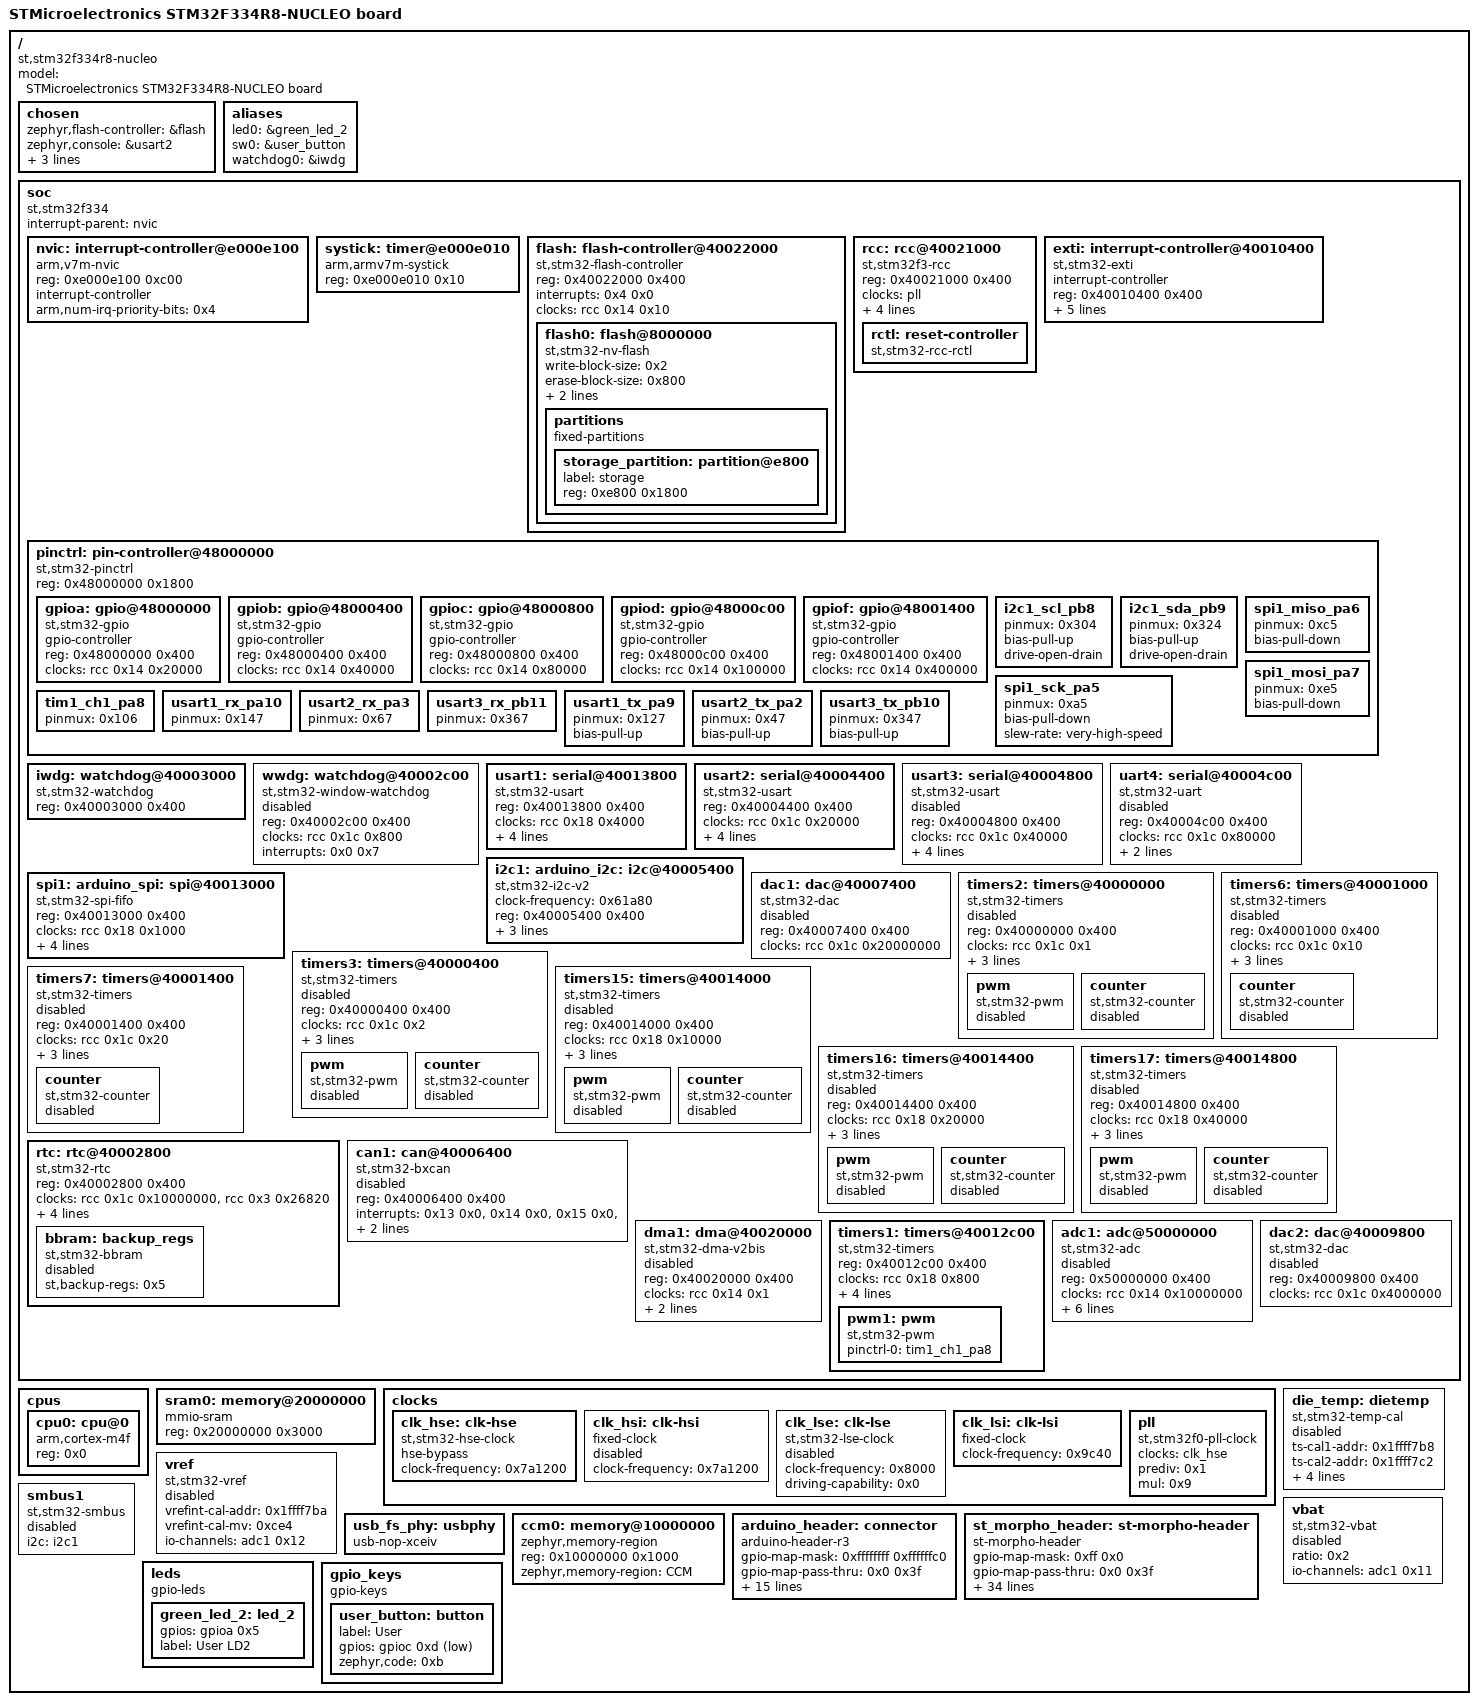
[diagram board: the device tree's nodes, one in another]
/dts-v1/;

/ {
	#address-cells = < 0x1 >;
	#size-cells = < 0x1 >;
	model = "STMicroelectronics STM32F334R8-NUCLEO board";
	compatible = "st,stm32f334r8-nucleo";
	chosen {
		zephyr,flash-controller = &flash;
		zephyr,console = &usart2;
		zephyr,shell-uart = &usart2;
		zephyr,sram = &sram0;
		zephyr,flash = &flash0;
	};
	aliases {
		led0 = &green_led_2;
		sw0 = &user_button;
		watchdog0 = &iwdg;
	};
	soc {
		#address-cells = < 0x1 >;
		#size-cells = < 0x1 >;
		compatible = "st,stm32f334", "st,stm32f3", "simple-bus";
		interrupt-parent = < &nvic >;
		ranges;
		nvic: interrupt-controller@e000e100 {
			#address-cells = < 0x1 >;
			compatible = "arm,v7m-nvic";
			reg = < 0xe000e100 0xc00 >;
			interrupt-controller;
			#interrupt-cells = < 0x2 >;
			arm,num-irq-priority-bits = < 0x4 >;
			phandle = < 0x1 >;
		};
		systick: timer@e000e010 {
			compatible = "arm,armv7m-systick";
			reg = < 0xe000e010 0x10 >;
		};
		flash: flash-controller@40022000 {
			compatible = "st,stm32-flash-controller", "st,stm32f1-flash-controller";
			reg = < 0x40022000 0x400 >;
			interrupts = < 0x4 0x0 >;
			clocks = < &rcc 0x14 0x10 >;
			#address-cells = < 0x1 >;
			#size-cells = < 0x1 >;
			flash0: flash@8000000 {
				compatible = "st,stm32-nv-flash", "soc-nv-flash";
				write-block-size = < 0x2 >;
				erase-block-size = < 0x800 >;
				max-erase-time = < 0x28 >;
				reg = < 0x8000000 0x10000 >;
				partitions {
					compatible = "fixed-partitions";
					#address-cells = < 0x1 >;
					#size-cells = < 0x1 >;
					storage_partition: partition@e800 {
						label = "storage";
						reg = < 0xe800 0x1800 >;
					};
				};
			};
		};
		rcc: rcc@40021000 {
			compatible = "st,stm32f3-rcc";
			#clock-cells = < 0x2 >;
			reg = < 0x40021000 0x400 >;
			clocks = < &pll >;
			clock-frequency = < 0x44aa200 >;
			ahb-prescaler = < 0x1 >;
			apb1-prescaler = < 0x2 >;
			apb2-prescaler = < 0x1 >;
			phandle = < 0x2 >;
			rctl: reset-controller {
				compatible = "st,stm32-rcc-rctl";
				#reset-cells = < 0x1 >;
				phandle = < 0x4 >;
			};
		};
		exti: interrupt-controller@40010400 {
			compatible = "st,stm32-exti";
			interrupt-controller;
			#interrupt-cells = < 0x1 >;
			#address-cells = < 0x1 >;
			reg = < 0x40010400 0x400 >;
			num-lines = < 0x10 >;
			interrupts = < 0x6 0x0 >, < 0x7 0x0 >, < 0x8 0x0 >, < 0x9 0x0 >, < 0xa 0x0 >, < 0x17 0x0 >, < 0x28 0x0 >;
			interrupt-names = "line0", "line1", "line2", "line3", "line4", "line5-9", "line10-15";
			line-ranges = < 0x0 0x1 >, < 0x1 0x1 >, < 0x2 0x1 >, < 0x3 0x1 >, < 0x4 0x1 >, < 0x5 0x5 >, < 0xa 0x6 >;
		};
		pinctrl: pin-controller@48000000 {
			compatible = "st,stm32-pinctrl";
			#address-cells = < 0x1 >;
			#size-cells = < 0x1 >;
			reg = < 0x48000000 0x1800 >;
			gpioa: gpio@48000000 {
				compatible = "st,stm32-gpio";
				gpio-controller;
				#gpio-cells = < 0x2 >;
				reg = < 0x48000000 0x400 >;
				clocks = < &rcc 0x14 0x20000 >;
				phandle = < 0x15 >;
			};
			gpiob: gpio@48000400 {
				compatible = "st,stm32-gpio";
				gpio-controller;
				#gpio-cells = < 0x2 >;
				reg = < 0x48000400 0x400 >;
				clocks = < &rcc 0x14 0x40000 >;
				phandle = < 0x10 >;
			};
			gpioc: gpio@48000800 {
				compatible = "st,stm32-gpio";
				gpio-controller;
				#gpio-cells = < 0x2 >;
				reg = < 0x48000800 0x400 >;
				clocks = < &rcc 0x14 0x80000 >;
				phandle = < 0x16 >;
			};
			gpiod: gpio@48000c00 {
				compatible = "st,stm32-gpio";
				gpio-controller;
				#gpio-cells = < 0x2 >;
				reg = < 0x48000c00 0x400 >;
				clocks = < &rcc 0x14 0x100000 >;
				phandle = < 0x17 >;
			};
			gpiof: gpio@48001400 {
				compatible = "st,stm32-gpio";
				gpio-controller;
				#gpio-cells = < 0x2 >;
				reg = < 0x48001400 0x400 >;
				clocks = < &rcc 0x14 0x400000 >;
				phandle = < 0x18 >;
			};
			i2c1_scl_pb8: i2c1_scl_pb8 {
				pinmux = < 0x304 >;
				bias-pull-up;
				drive-open-drain;
				phandle = < 0xb >;
			};
			i2c1_sda_pb9: i2c1_sda_pb9 {
				pinmux = < 0x324 >;
				bias-pull-up;
				drive-open-drain;
				phandle = < 0xc >;
			};
			spi1_miso_pa6: spi1_miso_pa6 {
				pinmux = < 0xc5 >;
				bias-pull-down;
				phandle = < 0xe >;
			};
			spi1_mosi_pa7: spi1_mosi_pa7 {
				pinmux = < 0xe5 >;
				bias-pull-down;
				phandle = < 0xf >;
			};
			spi1_sck_pa5: spi1_sck_pa5 {
				pinmux = < 0xa5 >;
				bias-pull-down;
				slew-rate = "very-high-speed";
				phandle = < 0xd >;
			};
			tim1_ch1_pa8: tim1_ch1_pa8 {
				pinmux = < 0x106 >;
				phandle = < 0x11 >;
			};
			usart1_rx_pa10: usart1_rx_pa10 {
				pinmux = < 0x147 >;
				phandle = < 0x6 >;
			};
			usart2_rx_pa3: usart2_rx_pa3 {
				pinmux = < 0x67 >;
				phandle = < 0x8 >;
			};
			usart3_rx_pb11: usart3_rx_pb11 {
				pinmux = < 0x367 >;
				phandle = < 0xa >;
			};
			usart1_tx_pa9: usart1_tx_pa9 {
				pinmux = < 0x127 >;
				bias-pull-up;
				phandle = < 0x5 >;
			};
			usart2_tx_pa2: usart2_tx_pa2 {
				pinmux = < 0x47 >;
				bias-pull-up;
				phandle = < 0x7 >;
			};
			usart3_tx_pb10: usart3_tx_pb10 {
				pinmux = < 0x347 >;
				bias-pull-up;
				phandle = < 0x9 >;
			};
		};
		iwdg: watchdog@40003000 {
			compatible = "st,stm32-watchdog";
			reg = < 0x40003000 0x400 >;
			status = "okay";
		};
		wwdg: watchdog@40002c00 {
			compatible = "st,stm32-window-watchdog";
			reg = < 0x40002c00 0x400 >;
			clocks = < &rcc 0x1c 0x800 >;
			interrupts = < 0x0 0x7 >;
			status = "disabled";
		};
		usart1: serial@40013800 {
			compatible = "st,stm32-usart", "st,stm32-uart";
			reg = < 0x40013800 0x400 >;
			clocks = < &rcc 0x18 0x4000 >;
			resets = < &rctl 0x18e >;
			interrupts = < 0x25 0x0 >;
			status = "okay";
			pinctrl-0 = < &usart1_tx_pa9 &usart1_rx_pa10 >;
			pinctrl-names = "default";
			current-speed = < 0x1c200 >;
		};
		usart2: serial@40004400 {
			compatible = "st,stm32-usart", "st,stm32-uart";
			reg = < 0x40004400 0x400 >;
			clocks = < &rcc 0x1c 0x20000 >;
			resets = < &rctl 0x211 >;
			interrupts = < 0x26 0x0 >;
			status = "okay";
			pinctrl-0 = < &usart2_tx_pa2 &usart2_rx_pa3 >;
			pinctrl-names = "default";
			current-speed = < 0x1c200 >;
		};
		usart3: serial@40004800 {
			compatible = "st,stm32-usart", "st,stm32-uart";
			reg = < 0x40004800 0x400 >;
			clocks = < &rcc 0x1c 0x40000 >;
			resets = < &rctl 0x212 >;
			interrupts = < 0x27 0x0 >;
			status = "disabled";
			pinctrl-0 = < &usart3_tx_pb10 &usart3_rx_pb11 >;
			pinctrl-names = "default";
			current-speed = < 0x1c200 >;
		};
		uart4: serial@40004c00 {
			compatible = "st,stm32-uart";
			reg = < 0x40004c00 0x400 >;
			clocks = < &rcc 0x1c 0x80000 >;
			resets = < &rctl 0x213 >;
			interrupts = < 0x34 0x0 >;
			status = "disabled";
		};
		i2c1: arduino_i2c: i2c@40005400 {
			compatible = "st,stm32-i2c-v2";
			clock-frequency = < 0x61a80 >;
			#address-cells = < 0x1 >;
			#size-cells = < 0x0 >;
			reg = < 0x40005400 0x400 >;
			clocks = < &rcc 0x1c 0x200000 >, < &rcc 0x1 0x12430 >;
			interrupts = < 0x1f 0x0 >, < 0x20 0x0 >;
			interrupt-names = "event", "error";
			status = "okay";
			pinctrl-0 = < &i2c1_scl_pb8 &i2c1_sda_pb9 >;
			pinctrl-names = "default";
			phandle = < 0x14 >;
		};
		spi1: arduino_spi: spi@40013000 {
			compatible = "st,stm32-spi-fifo", "st,stm32-spi";
			#address-cells = < 0x1 >;
			#size-cells = < 0x0 >;
			reg = < 0x40013000 0x400 >;
			clocks = < &rcc 0x18 0x1000 >;
			interrupts = < 0x23 0x5 >;
			status = "okay";
			pinctrl-0 = < &spi1_sck_pa5 &spi1_miso_pa6 &spi1_mosi_pa7 >;
			pinctrl-names = "default";
			cs-gpios = < &gpiob 0x6 0x11 >;
		};
		dac1: dac@40007400 {
			compatible = "st,stm32-dac";
			reg = < 0x40007400 0x400 >;
			clocks = < &rcc 0x1c 0x20000000 >;
			status = "disabled";
			#io-channel-cells = < 0x1 >;
		};
		timers2: timers@40000000 {
			compatible = "st,stm32-timers";
			reg = < 0x40000000 0x400 >;
			clocks = < &rcc 0x1c 0x1 >;
			resets = < &rctl 0x200 >;
			interrupts = < 0x1c 0x0 >;
			interrupt-names = "global";
			st,prescaler = < 0x0 >;
			status = "disabled";
			pwm {
				compatible = "st,stm32-pwm";
				status = "disabled";
				#pwm-cells = < 0x3 >;
			};
			counter {
				compatible = "st,stm32-counter";
				status = "disabled";
			};
		};
		timers3: timers@40000400 {
			compatible = "st,stm32-timers";
			reg = < 0x40000400 0x400 >;
			clocks = < &rcc 0x1c 0x2 >;
			resets = < &rctl 0x201 >;
			interrupts = < 0x1d 0x0 >;
			interrupt-names = "global";
			st,prescaler = < 0x0 >;
			status = "disabled";
			pwm {
				compatible = "st,stm32-pwm";
				status = "disabled";
				#pwm-cells = < 0x3 >;
			};
			counter {
				compatible = "st,stm32-counter";
				status = "disabled";
			};
		};
		timers6: timers@40001000 {
			compatible = "st,stm32-timers";
			reg = < 0x40001000 0x400 >;
			clocks = < &rcc 0x1c 0x10 >;
			resets = < &rctl 0x204 >;
			interrupts = < 0x36 0x0 >;
			interrupt-names = "global";
			st,prescaler = < 0x0 >;
			status = "disabled";
			counter {
				compatible = "st,stm32-counter";
				status = "disabled";
			};
		};
		timers7: timers@40001400 {
			compatible = "st,stm32-timers";
			reg = < 0x40001400 0x400 >;
			clocks = < &rcc 0x1c 0x20 >;
			resets = < &rctl 0x205 >;
			interrupts = < 0x37 0x0 >;
			interrupt-names = "global";
			st,prescaler = < 0x0 >;
			status = "disabled";
			counter {
				compatible = "st,stm32-counter";
				status = "disabled";
			};
		};
		timers15: timers@40014000 {
			compatible = "st,stm32-timers";
			reg = < 0x40014000 0x400 >;
			clocks = < &rcc 0x18 0x10000 >;
			resets = < &rctl 0x190 >;
			interrupts = < 0x18 0x0 >;
			interrupt-names = "global";
			st,prescaler = < 0x0 >;
			status = "disabled";
			pwm {
				compatible = "st,stm32-pwm";
				status = "disabled";
				#pwm-cells = < 0x3 >;
			};
			counter {
				compatible = "st,stm32-counter";
				status = "disabled";
			};
		};
		timers16: timers@40014400 {
			compatible = "st,stm32-timers";
			reg = < 0x40014400 0x400 >;
			clocks = < &rcc 0x18 0x20000 >;
			resets = < &rctl 0x191 >;
			interrupts = < 0x19 0x0 >;
			interrupt-names = "global";
			st,prescaler = < 0x0 >;
			status = "disabled";
			pwm {
				compatible = "st,stm32-pwm";
				status = "disabled";
				#pwm-cells = < 0x3 >;
			};
			counter {
				compatible = "st,stm32-counter";
				status = "disabled";
			};
		};
		timers17: timers@40014800 {
			compatible = "st,stm32-timers";
			reg = < 0x40014800 0x400 >;
			clocks = < &rcc 0x18 0x40000 >;
			resets = < &rctl 0x192 >;
			interrupts = < 0x1a 0x0 >;
			interrupt-names = "global";
			st,prescaler = < 0x0 >;
			status = "disabled";
			pwm {
				compatible = "st,stm32-pwm";
				status = "disabled";
				#pwm-cells = < 0x3 >;
			};
			counter {
				compatible = "st,stm32-counter";
				status = "disabled";
			};
		};
		rtc: rtc@40002800 {
			compatible = "st,stm32-rtc";
			reg = < 0x40002800 0x400 >;
			clocks = < &rcc 0x1c 0x10000000 >, < &rcc 0x3 0x26820 >;
			interrupts = < 0x29 0x0 >;
			prescaler = < 0x8000 >;
			alarms-count = < 0x2 >;
			alrm-exti-line = < 0x11 >;
			status = "okay";
			bbram: backup_regs {
				compatible = "st,stm32-bbram";
				st,backup-regs = < 0x5 >;
				status = "disabled";
			};
		};
		can1: can@40006400 {
			compatible = "st,stm32-bxcan";
			reg = < 0x40006400 0x400 >;
			interrupts = < 0x13 0x0 >, < 0x14 0x0 >, < 0x15 0x0 >, < 0x16 0x0 >;
			interrupt-names = "TX", "RX0", "RX1", "SCE";
			clocks = < &rcc 0x1c 0x2000000 >;
			status = "disabled";
		};
		dma1: dma@40020000 {
			compatible = "st,stm32-dma-v2bis";
			#dma-cells = < 0x2 >;
			reg = < 0x40020000 0x400 >;
			clocks = < &rcc 0x14 0x1 >;
			interrupts = < 0xb 0x0 0xc 0x0 0xd 0x0 0xe 0x0 0xf 0x0 0x10 0x0 0x11 0x0 >;
			status = "disabled";
		};
		timers1: timers@40012c00 {
			compatible = "st,stm32-timers";
			reg = < 0x40012c00 0x400 >;
			clocks = < &rcc 0x18 0x800 >;
			resets = < &rctl 0x18b >;
			interrupts = < 0x18 0x0 >, < 0x19 0x0 >, < 0x1a 0x0 >, < 0x1b 0x0 >;
			interrupt-names = "brk", "up", "trgcom", "cc";
			st,prescaler = < 0x2710 >;
			status = "okay";
			pwm1: pwm {
				compatible = "st,stm32-pwm";
				status = "okay";
				#pwm-cells = < 0x3 >;
				pinctrl-0 = < &tim1_ch1_pa8 >;
				pinctrl-names = "default";
			};
		};
		adc1: adc@50000000 {
			compatible = "st,stm32-adc";
			reg = < 0x50000000 0x400 >;
			clocks = < &rcc 0x14 0x10000000 >;
			interrupts = < 0x12 0x0 >;
			status = "disabled";
			#io-channel-cells = < 0x1 >;
			resolutions = < 0x60630c 0x51630c 0x42630c 0x33630c >;
			sampling-times = < 0x2 0x3 0x5 0x8 0x14 0x3e 0xb6 0x25a >;
			st,adc-sequencer = < 0x1 >;
			phandle = < 0x13 >;
		};
		dac2: dac@40009800 {
			compatible = "st,stm32-dac";
			reg = < 0x40009800 0x400 >;
			clocks = < &rcc 0x1c 0x4000000 >;
			status = "disabled";
			#io-channel-cells = < 0x1 >;
		};
	};
	cpus {
		#address-cells = < 0x1 >;
		#size-cells = < 0x0 >;
		cpu0: cpu@0 {
			device_type = "cpu";
			compatible = "arm,cortex-m4f";
			reg = < 0x0 >;
		};
	};
	sram0: memory@20000000 {
		compatible = "mmio-sram";
		reg = < 0x20000000 0x3000 >;
	};
	clocks {
		clk_hse: clk-hse {
			#clock-cells = < 0x0 >;
			compatible = "st,stm32-hse-clock";
			status = "okay";
			hse-bypass;
			clock-frequency = < 0x7a1200 >;
			phandle = < 0x12 >;
		};
		clk_hsi: clk-hsi {
			#clock-cells = < 0x0 >;
			compatible = "fixed-clock";
			clock-frequency = < 0x7a1200 >;
			status = "disabled";
		};
		clk_lse: clk-lse {
			#clock-cells = < 0x0 >;
			compatible = "st,stm32-lse-clock";
			clock-frequency = < 0x8000 >;
			driving-capability = < 0x0 >;
			status = "disabled";
		};
		clk_lsi: clk-lsi {
			#clock-cells = < 0x0 >;
			compatible = "fixed-clock";
			clock-frequency = < 0x9c40 >;
			status = "okay";
		};
		pll: pll {
			#clock-cells = < 0x0 >;
			compatible = "st,stm32f0-pll-clock";
			status = "okay";
			clocks = < &clk_hse >;
			prediv = < 0x1 >;
			mul = < 0x9 >;
			phandle = < 0x3 >;
		};
	};
	die_temp: dietemp {
		compatible = "st,stm32-temp-cal";
		ts-cal1-addr = < 0x1ffff7b8 >;
		ts-cal2-addr = < 0x1ffff7c2 >;
		ts-cal1-temp = < 0x1e >;
		ts-cal2-temp = < 0x6e >;
		ts-cal-vrefanalog = < 0xce4 >;
		io-channels = < &adc1 0x10 >;
		status = "disabled";
	};
	vref: vref {
		compatible = "st,stm32-vref";
		vrefint-cal-addr = < 0x1ffff7ba >;
		vrefint-cal-mv = < 0xce4 >;
		io-channels = < &adc1 0x12 >;
		status = "disabled";
	};
	vbat: vbat {
		compatible = "st,stm32-vbat";
		ratio = < 0x2 >;
		io-channels = < &adc1 0x11 >;
		status = "disabled";
	};
	usb_fs_phy: usbphy {
		compatible = "usb-nop-xceiv";
		#phy-cells = < 0x0 >;
	};
	smbus1: smbus1 {
		compatible = "st,stm32-smbus";
		#address-cells = < 0x1 >;
		#size-cells = < 0x0 >;
		i2c = < &i2c1 >;
		status = "disabled";
	};
	ccm0: memory@10000000 {
		compatible = "zephyr,memory-region", "st,stm32-ccm";
		reg = < 0x10000000 0x1000 >;
		zephyr,memory-region = "CCM";
	};
	arduino_header: connector {
		compatible = "arduino-header-r3";
		#gpio-cells = < 0x2 >;
		gpio-map-mask = < 0xffffffff 0xffffffc0 >;
		gpio-map-pass-thru = < 0x0 0x3f >;
		gpio-map = < 0x0 0x0 &gpioa 0x0 0x0 >, < 0x1 0x0 &gpioa 0x1 0x0 >, < 0x2 0x0 &gpioa 0x4 0x0 >, < 0x3 0x0 &gpiob 0x0 0x0 >, < 0x4 0x0 &gpioc 0x1 0x0 >, < 0x5 0x0 &gpioc 0x0 0x0 >, < 0x6 0x0 &gpioa 0x3 0x0 >, < 0x7 0x0 &gpioa 0x2 0x0 >, < 0x8 0x0 &gpioa 0xa 0x0 >, < 0x9 0x0 &gpiob 0x3 0x0 >, < 0xa 0x0 &gpiob 0x5 0x0 >, < 0xb 0x0 &gpiob 0x4 0x0 >, < 0xc 0x0 &gpiob 0xa 0x0 >, < 0xd 0x0 &gpioa 0x8 0x0 >, < 0xe 0x0 &gpioa 0x9 0x0 >, < 0xf 0x0 &gpioc 0x7 0x0 >, < 0x10 0x0 &gpiob 0x6 0x0 >, < 0x11 0x0 &gpioa 0x7 0x0 >, < 0x12 0x0 &gpioa 0x6 0x0 >, < 0x13 0x0 &gpioa 0x5 0x0 >, < 0x14 0x0 &gpiob 0x9 0x0 >, < 0x15 0x0 &gpiob 0x8 0x0 >;
	};
	st_morpho_header: st-morpho-header {
		compatible = "st-morpho-header";
		#gpio-cells = < 0x2 >;
		gpio-map-mask = < 0xff 0x0 >;
		gpio-map-pass-thru = < 0x0 0x3f >;
		gpio-map = < 0x0 0x0 &gpioc 0xa 0x0 >, < 0x1 0x0 &gpioc 0xb 0x0 >, < 0x2 0x0 &gpioc 0xc 0x0 >, < 0x3 0x0 &gpiod 0x2 0x0 >, < 0xc 0x0 &gpioa 0xd 0x0 >, < 0xe 0x0 &gpioa 0xe 0x0 >, < 0x10 0x0 &gpioa 0xf 0x0 >, < 0x14 0x0 &gpiob 0x7 0x0 >, < 0x16 0x0 &gpioc 0xd 0x0 >, < 0x18 0x0 &gpioc 0xe 0x0 >, < 0x1a 0x0 &gpioc 0xf 0x0 >, < 0x1b 0x0 &gpioa 0x0 0x0 >, < 0x1c 0x0 &gpiof 0x0 0x0 >, < 0x1d 0x0 &gpioa 0x1 0x0 >, < 0x1e 0x0 &gpiof 0x1 0x0 >, < 0x1f 0x0 &gpioa 0x4 0x0 >, < 0x21 0x0 &gpiob 0x0 0x0 >, < 0x22 0x0 &gpioc 0x2 0x0 >, < 0x23 0x0 &gpioc 0x1 0x0 >, < 0x24 0x0 &gpioc 0x3 0x0 >, < 0x25 0x0 &gpioc 0x0 0x0 >, < 0x48 0x0 &gpioc 0x9 0x0 >, < 0x49 0x0 &gpioc 0x8 0x0 >, < 0x4a 0x0 &gpiob 0x8 0x0 >, < 0x4b 0x0 &gpioc 0x6 0x0 >, < 0x4c 0x0 &gpiob 0x9 0x0 >, < 0x4d 0x0 &gpioc 0x5 0x0 >, < 0x52 0x0 &gpioa 0x5 0x0 >, < 0x53 0x0 &gpioa 0xc 0x0 >, < 0x54 0x0 &gpioa 0x6 0x0 >, < 0x55 0x0 &gpioa 0xb 0x0 >, < 0x56 0x0 &gpioa 0x7 0x0 >, < 0x57 0x0 &gpiob 0xc 0x0 >, < 0x58 0x0 &gpiob 0x6 0x0 >, < 0x59 0x0 &gpiob 0xb 0x0 >, < 0x5a 0x0 &gpioc 0x7 0x0 >, < 0x5c 0x0 &gpioa 0x9 0x0 >, < 0x5d 0x0 &gpiob 0x2 0x0 >, < 0x5e 0x0 &gpioa 0x8 0x0 >, < 0x5f 0x0 &gpiob 0x1 0x0 >, < 0x60 0x0 &gpiob 0xa 0x0 >, < 0x61 0x0 &gpiob 0xf 0x0 >, < 0x62 0x0 &gpiob 0x4 0x0 >, < 0x63 0x0 &gpiob 0xe 0x0 >, < 0x64 0x0 &gpiob 0x5 0x0 >, < 0x65 0x0 &gpiob 0xd 0x0 >, < 0x66 0x0 &gpiob 0x3 0x0 >, < 0x68 0x0 &gpioa 0xa 0x0 >, < 0x69 0x0 &gpioc 0x4 0x0 >, < 0x6a 0x0 &gpioa 0x2 0x0 >, < 0x6c 0x0 &gpioa 0x3 0x0 >;
	};
	leds: leds {
		compatible = "gpio-leds";
		green_led_2: led_2 {
			gpios = < &gpioa 0x5 0x0 >;
			label = "User LD2";
		};
	};
	gpio_keys {
		compatible = "gpio-keys";
		user_button: button {
			label = "User";
			gpios = < &gpioc 0xd 0x1 >;
			zephyr,code = < 0xb >;
		};
	};
};
